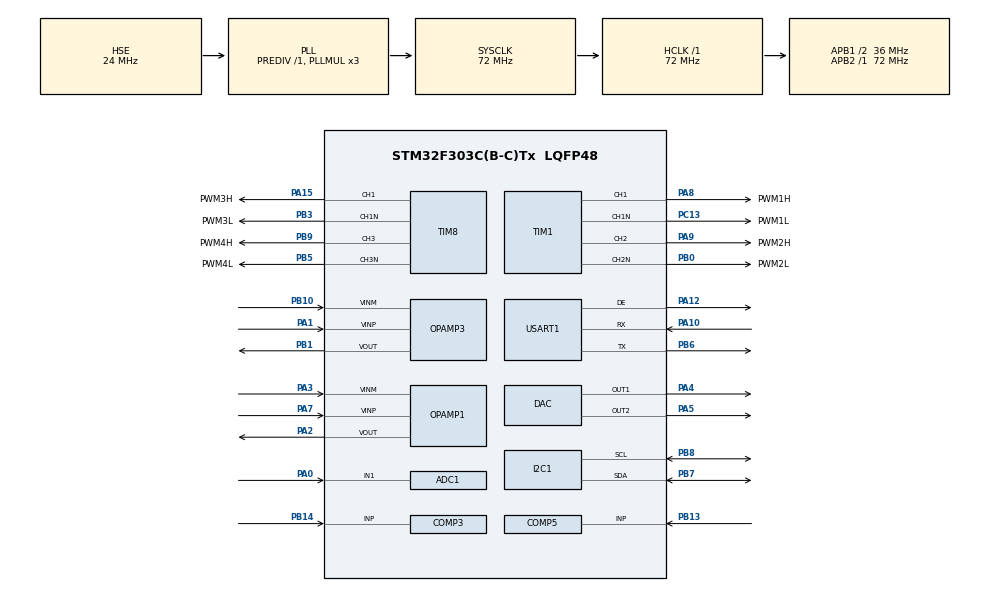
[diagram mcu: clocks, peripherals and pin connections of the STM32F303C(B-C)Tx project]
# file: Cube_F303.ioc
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ADC1.Channel-0\#ChannelRegularConversion=ADC_CHANNEL_VBAT
ADC1.NbrOfConversionFlag=1
ADC1.Offset-0\#ChannelRegularConversion=0
ADC1.OffsetNumber-0\#ChannelRegularConversion=ADC_OFFSET_NONE
ADC1.Rank-0\#ChannelRegularConversion=1
ADC1.SamplingTime-0\#ChannelRegularConversion=ADC_SAMPLETIME_1CYCLE_5
ADC1.master=1
COMP3.InvertingInput=COMP_INVERTINGINPUT_DAC1_CH1
COMP5.InvertingInput=COMP_INVERTINGINPUT_DAC1_CH2
Dma.ADC1.0.Direction=DMA_PERIPH_TO_MEMORY
Dma.ADC1.0.Instance=DMA1_Channel1
Dma.ADC1.0.MemDataAlignment=DMA_MDATAALIGN_HALFWORD
Dma.ADC1.0.MemInc=DMA_MINC_ENABLE
Dma.ADC1.0.Mode=DMA_CIRCULAR
Dma.ADC1.0.PeriphDataAlignment=DMA_PDATAALIGN_HALFWORD
Dma.ADC1.0.PeriphInc=DMA_PINC_DISABLE
Dma.ADC1.0.Priority=DMA_PRIORITY_LOW
Dma.Request0=ADC1
Mcu.Family=STM32F3
Mcu.Name=STM32F303C(B-C)Tx
Mcu.Package=LQFP48
NVIC.DMA1_Channel1_IRQn=true\:0\:0\:false\:false\:true
NVIC.PriorityGroup=NVIC_PRIORITYGROUP_4
NVIC.TIM6_DAC_IRQn=true\:0\:0\:false\:false\:true
PA0.Mode=IN1-Single-Ended
PA0.Signal=ADC1_IN1
PA1.Mode=Standalone
PA1.Signal=OPAMP3_VINP
PA10.Mode=Asynchronous
PA10.Signal=USART1_RX
PA12.Mode=Hardware Flow Control (RS485)
PA12.Signal=USART1_DE
PA13.Mode=Serial_Wire
PA13.Signal=SYS_JTMS-SWDIO
PA14.Mode=Serial_Wire
PA14.Signal=SYS_JTCK-SWCLK
PA15.GPIO_Label=PWM3H
PA15.Signal=S_TIM8_CH1
PA2.Mode=Standalone
PA2.Signal=OPAMP1_VOUT
PA3.Mode=Standalone
PA3.Signal=OPAMP1_VINM
PA4.Signal=COMP_DAC1_group
PA5.Signal=COMP_DAC2_group
PA7.Mode=Standalone
PA7.Signal=OPAMP1_VINP
PA8.GPIO_Label=PWM1H
PA8.Signal=S_TIM1_CH1
PA9.GPIO_Label=PWM2H
PA9.Signal=S_TIM1_CH2
PB0.GPIO_Label=PWM2L
PB0.Mode=Output Compare2 CH2 CH2N
PB0.Signal=TIM1_CH2N
PB1.Mode=Standalone
PB1.Signal=OPAMP3_VOUT
PB10.Mode=Standalone
PB10.Signal=OPAMP3_VINM
PB13.Mode=INP
PB13.Signal=COMP5_INP
PB14.Mode=INP
PB14.Signal=COMP3_INP
PB3.GPIO_Label=PWM3L
PB3.Mode=Output Compare1 CH1 CH1N
PB3.Signal=TIM8_CH1N
PB5.GPIO_Label=PWM4L
PB5.Mode=Output Compare3 CH3 CH3N
PB5.Signal=TIM8_CH3N
PB6.Mode=Asynchronous
PB6.Signal=USART1_TX
PB7.Mode=I2C
PB7.Signal=I2C1_SDA
PB8.Mode=I2C
PB8.Signal=I2C1_SCL
PB9.GPIO_Label=PWM4H
PB9.Signal=S_TIM8_CH3
PC13.GPIO_Label=PWM1L
PC13.Mode=Output Compare1 CH1 CH1N
PC13.Signal=TIM1_CH1N
PF0-OSC_IN.Mode=HSE-External-Oscillator
PF0-OSC_IN.Signal=RCC_OSC_IN
PF1-OSC_OUT.Mode=HSE-External-Oscillator
PF1-OSC_OUT.Signal=RCC_OSC_OUT
ProjectManager.HeapSize=0x200
ProjectManager.StackSize=0x400
ProjectManager.TargetToolchain=Other Toolchains (GPDSC)
RCC.AHBFreq_Value=72000000
RCC.APB1CLKDivider=RCC_HCLK_DIV2
RCC.APB1Freq_Value=36000000
RCC.APB1TimFreq_Value=72000000
RCC.APB2Freq_Value=72000000
RCC.APB2TimFreq_Value=72000000
RCC.CortexFreq_Value=9000000
RCC.Cortex_Div=SYSTICK_CLKSOURCE_HCLK_DIV8
RCC.HCLKFreq_Value=72000000
RCC.HSE_VALUE=24000000
RCC.HSI_VALUE=8000000
RCC.LSE_VALUE=32768
RCC.PLLMUL=RCC_PLL_MUL3
RCC.PLLSourceVirtual=RCC_PLLSOURCE_HSE
RCC.SYSCLKFreq_VALUE=72000000
RCC.TIM1Selection=RCC_TIM1CLK_PLLCLK
RCC.TIM8Selection=RCC_TIM8CLK_PLLCLK
RCC.USBFreq_Value=72000000
RCC.Usart1ClockSelection=RCC_USART1CLKSOURCE_HSI
SH.COMP_DAC1_group.0=DAC_OUT1,DAC_OUT1
SH.COMP_DAC2_group.0=DAC_OUT2,Enable_DAC_OUT2
SH.S_TIM1_CH1.0=TIM1_CH1,Output Compare1 CH1 CH1N
SH.S_TIM1_CH2.0=TIM1_CH2,Output Compare2 CH2 CH2N
SH.S_TIM8_CH1.0=TIM8_CH1,Output Compare1 CH1 CH1N
SH.S_TIM8_CH3.0=TIM8_CH3,Output Compare3 CH3 CH3N
TIM1.Channel-Output\ Compare1\ CH1\ CH1N=TIM_CHANNEL_1
TIM1.Channel-Output\ Compare2\ CH2\ CH2N=TIM_CHANNEL_2
TIM6.Period=1000
TIM8.Channel-Output\ Compare1\ CH1\ CH1N=TIM_CHANNEL_1
TIM8.Channel-Output\ Compare3\ CH3\ CH3N=TIM_CHANNEL_3
USART1.VirtualMode-Asynchronous=VM_ASYNC
USART1.VirtualMode-Hardware\ Flow\ Control\ (RS485)=VM_ASYNC
VP_ADC1_TempSens_Input.Mode=IN-TempSens
VP_ADC1_Vbat_Input.Mode=IN-Vbat
VP_COMP3_VS_DAC1OUT1.Mode=INM_DACOUT1
VP_COMP5_VS_DAC1OUT2.Mode=INM_DACOUT2
VP_CRC_VS_CRC.Mode=CRC_Activate
VP_TIM6_VS_ClockSourceINT.Mode=Enable_Timer
board=Cube_F303

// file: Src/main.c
/**
  ******************************************************************************
  * File Name          : main.c
  * Description        : Main program body
  ******************************************************************************
  ** This notice applies to any and all portions of this file
  * that are not between comment pairs USER CODE BEGIN and
  * USER CODE END. Other portions of this file, whether
  * inserted by the user or by software development tools
  * are owned by their respective copyright owners.
  *
  * COPYRIGHT(c) 2017 STMicroelectronics
  *
  * Redistribution and use in source and binary forms, with or without modification,
  * are permitted provided that the following conditions are met:
  *   1. Redistributions of source code must retain the above copyright notice,
  *      this list of conditions and the following disclaimer.
  *   2. Redistributions in binary form must reproduce the above copyright notice,
  *      this list of conditions and the following disclaimer in the documentation
  *      and/or other materials provided with the distribution.
  *   3. Neither the name of STMicroelectronics nor the names of its contributors
  *      may be used to endorse or promote products derived from this software
  *      without specific prior written permission.
  *
  * THIS SOFTWARE IS PROVIDED BY THE COPYRIGHT HOLDERS AND CONTRIBUTORS "AS IS"
  * AND ANY EXPRESS OR IMPLIED WARRANTIES, INCLUDING, BUT NOT LIMITED TO, THE
  * IMPLIED WARRANTIES OF MERCHANTABILITY AND FITNESS FOR A PARTICULAR PURPOSE ARE
  * DISCLAIMED. IN NO EVENT SHALL THE COPYRIGHT HOLDER OR CONTRIBUTORS BE LIABLE
  * FOR ANY DIRECT, INDIRECT, INCIDENTAL, SPECIAL, EXEMPLARY, OR CONSEQUENTIAL
  * DAMAGES (INCLUDING, BUT NOT LIMITED TO, PROCUREMENT OF SUBSTITUTE GOODS OR
  * SERVICES; LOSS OF USE, DATA, OR PROFITS; OR BUSINESS INTERRUPTION) HOWEVER
  * CAUSED AND ON ANY THEORY OF LIABILITY, WHETHER IN CONTRACT, STRICT LIABILITY,
  * OR TORT (INCLUDING NEGLIGENCE OR OTHERWISE) ARISING IN ANY WAY OUT OF THE USE
  * OF THIS SOFTWARE, EVEN IF ADVISED OF THE POSSIBILITY OF SUCH DAMAGE.
  *
  ******************************************************************************
  */
#include "main.h"
#include "stm32f3xx_hal.h"

/* USER CODE BEGIN Includes */
#include "irq.h"
/* USER CODE END Includes */

ADC_HandleTypeDef hadc1;
DMA_HandleTypeDef hdma_adc1;

COMP_HandleTypeDef hcomp3;
COMP_HandleTypeDef hcomp5;

CRC_HandleTypeDef hcrc;

DAC_HandleTypeDef hdac;

I2C_HandleTypeDef hi2c1;

OPAMP_HandleTypeDef hopamp1;
OPAMP_HandleTypeDef hopamp3;

TIM_HandleTypeDef htim1;
TIM_HandleTypeDef htim6;
TIM_HandleTypeDef htim8;

UART_HandleTypeDef huart1;

/* USER CODE BEGIN PV */

/**
Timer TIM6 delay formavimas

*/

/* Private variables ---------------------------------------------------------*/

/* USER CODE END PV */

void SystemClock_Config(void);
static void MX_GPIO_Init(void);
static void MX_DMA_Init(void);
static void MX_DAC_Init(void);
static void MX_I2C1_Init(void);
static void MX_USART1_UART_Init(void);
static void MX_TIM1_Init(void);
static void MX_TIM8_Init(void);
static void MX_OPAMP1_Init(void);
static void MX_OPAMP3_Init(void);
static void MX_COMP3_Init(void);
static void MX_COMP5_Init(void);
static void MX_ADC1_Init(void);
static void MX_TIM6_Init(void);
static void MX_CRC_Init(void);

void HAL_TIM_MspPostInit(TIM_HandleTypeDef *htim);

/* USER CODE BEGIN PFP */
/* Private function prototypes -----------------------------------------------*/

/* USER CODE END PFP */

int main(void)
{

  /* USER CODE BEGIN 1 */
    disable_interrupts();
  /* USER CODE END 1 */

  /* MCU Configuration----------------------------------------------------------*/

  /* Reset of all peripherals, Initializes the Flash interface and the Systick. */
  HAL_Init();

  /* Configure the system clock */
  SystemClock_Config();

  /* Initialize all configured peripherals */
  MX_GPIO_Init();
  MX_DMA_Init();
  MX_DAC_Init();
  MX_I2C1_Init();
  MX_USART1_UART_Init();
  MX_TIM1_Init();
  MX_TIM8_Init();
  MX_OPAMP1_Init();
  MX_OPAMP3_Init();
  MX_COMP3_Init();
  MX_COMP5_Init();
  MX_ADC1_Init();
  MX_TIM6_Init();
  MX_CRC_Init();

  /* Infinite loop */
  while (1)
  {

  }

}

/** System Clock Configuration
*/
void SystemClock_Config(void)
{

  RCC_OscInitTypeDef RCC_OscInitStruct;
  RCC_ClkInitTypeDef RCC_ClkInitStruct;
  RCC_PeriphCLKInitTypeDef PeriphClkInit;

    /**Initializes the CPU, AHB and APB busses clocks
    */
  RCC_OscInitStruct.OscillatorType = RCC_OSCILLATORTYPE_HSI|RCC_OSCILLATORTYPE_HSE;
  RCC_OscInitStruct.HSEState = RCC_HSE_ON;
  RCC_OscInitStruct.HSEPredivValue = RCC_HSE_PREDIV_DIV1;
  RCC_OscInitStruct.HSIState = RCC_HSI_ON;
  RCC_OscInitStruct.HSICalibrationValue = 16;
  RCC_OscInitStruct.PLL.PLLState = RCC_PLL_ON;
  RCC_OscInitStruct.PLL.PLLSource = RCC_PLLSOURCE_HSE;
  RCC_OscInitStruct.PLL.PLLMUL = RCC_PLL_MUL3;
  if (HAL_RCC_OscConfig(&RCC_OscInitStruct) != HAL_OK)
  {
    _Error_Handler(__FILE__, __LINE__);
  }

    /**Initializes the CPU, AHB and APB busses clocks
    */
  RCC_ClkInitStruct.ClockType = RCC_CLOCKTYPE_HCLK|RCC_CLOCKTYPE_SYSCLK
                              |RCC_CLOCKTYPE_PCLK1|RCC_CLOCKTYPE_PCLK2;
  RCC_ClkInitStruct.SYSCLKSource = RCC_SYSCLKSOURCE_PLLCLK;
  RCC_ClkInitStruct.AHBCLKDivider = RCC_SYSCLK_DIV1;
  RCC_ClkInitStruct.APB1CLKDivider = RCC_HCLK_DIV2;
  RCC_ClkInitStruct.APB2CLKDivider = RCC_HCLK_DIV1;

  if (HAL_RCC_ClockConfig(&RCC_ClkInitStruct, FLASH_LATENCY_2) != HAL_OK)
  {
    _Error_Handler(__FILE__, __LINE__);
  }

  PeriphClkInit.PeriphClockSelection = RCC_PERIPHCLK_USART1|RCC_PERIPHCLK_I2C1
                              |RCC_PERIPHCLK_TIM1|RCC_PERIPHCLK_TIM8
                              |RCC_PERIPHCLK_ADC12;
  PeriphClkInit.Usart1ClockSelection = RCC_USART1CLKSOURCE_HSI;
  PeriphClkInit.Adc12ClockSelection = RCC_ADC12PLLCLK_DIV1;
  PeriphClkInit.I2c1ClockSelection = RCC_I2C1CLKSOURCE_HSI;
  PeriphClkInit.Tim1ClockSelection = RCC_TIM1CLK_PLLCLK;
  PeriphClkInit.Tim8ClockSelection = RCC_TIM8CLK_PLLCLK;
  if (HAL_RCCEx_PeriphCLKConfig(&PeriphClkInit) != HAL_OK)
  {
    _Error_Handler(__FILE__, __LINE__);
  }

    /**Configure the Systick interrupt time
    */
  HAL_SYSTICK_Config(HAL_RCC_GetHCLKFreq()/8000);

    /**Configure the Systick
    */
  HAL_SYSTICK_CLKSourceConfig(SYSTICK_CLKSOURCE_HCLK_DIV8);

  /* SysTick_IRQn interrupt configuration */
  HAL_NVIC_SetPriority(SysTick_IRQn, 0, 0);
}

/* ADC1 init function */
static void MX_ADC1_Init(void)
{

  ADC_MultiModeTypeDef multimode;
  ADC_ChannelConfTypeDef sConfig;

    /**Common config
    */
  hadc1.Instance = ADC1;
  hadc1.Init.ClockPrescaler = ADC_CLOCK_ASYNC_DIV1;
  hadc1.Init.Resolution = ADC_RESOLUTION_12B;
  hadc1.Init.ScanConvMode = ADC_SCAN_DISABLE;
  hadc1.Init.ContinuousConvMode = DISABLE;
  hadc1.Init.DiscontinuousConvMode = DISABLE;
  hadc1.Init.ExternalTrigConvEdge = ADC_EXTERNALTRIGCONVEDGE_NONE;
  hadc1.Init.ExternalTrigConv = ADC_SOFTWARE_START;
  hadc1.Init.DataAlign = ADC_DATAALIGN_RIGHT;
  hadc1.Init.NbrOfConversion = 1;
  hadc1.Init.DMAContinuousRequests = DISABLE;
  hadc1.Init.EOCSelection = ADC_EOC_SINGLE_CONV;
  hadc1.Init.LowPowerAutoWait = DISABLE;
  hadc1.Init.Overrun = ADC_OVR_DATA_OVERWRITTEN;
  if (HAL_ADC_Init(&hadc1) != HAL_OK)
  {
    _Error_Handler(__FILE__, __LINE__);
  }

    /**Configure the ADC multi-mode
    */
  multimode.Mode = ADC_MODE_INDEPENDENT;
  if (HAL_ADCEx_MultiModeConfigChannel(&hadc1, &multimode) != HAL_OK)
  {
    _Error_Handler(__FILE__, __LINE__);
  }

    /**Configure Regular Channel
    */
  sConfig.Channel = ADC_CHANNEL_VBAT;
  sConfig.Rank = 1;
  sConfig.SingleDiff = ADC_SINGLE_ENDED;
  sConfig.SamplingTime = ADC_SAMPLETIME_1CYCLE_5;
  sConfig.OffsetNumber = ADC_OFFSET_NONE;
  sConfig.Offset = 0;
  if (HAL_ADC_ConfigChannel(&hadc1, &sConfig) != HAL_OK)
  {
    _Error_Handler(__FILE__, __LINE__);
  }

}

/* COMP3 init function */
static void MX_COMP3_Init(void)
{

  hcomp3.Instance = COMP3;
  hcomp3.Init.InvertingInput = COMP_INVERTINGINPUT_DAC1_CH1;
  hcomp3.Init.NonInvertingInput = COMP_NONINVERTINGINPUT_IO1;
  hcomp3.Init.Output = COMP_OUTPUT_NONE;
  hcomp3.Init.OutputPol = COMP_OUTPUTPOL_NONINVERTED;
  hcomp3.Init.Hysteresis = COMP_HYSTERESIS_NONE;
  hcomp3.Init.BlankingSrce = COMP_BLANKINGSRCE_NONE;
  hcomp3.Init.Mode = COMP_MODE_HIGHSPEED;
  hcomp3.Init.WindowMode = COMP_WINDOWMODE_DISABLE;
  hcomp3.Init.TriggerMode = COMP_TRIGGERMODE_NONE;
  if (HAL_COMP_Init(&hcomp3) != HAL_OK)
  {
    _Error_Handler(__FILE__, __LINE__);
  }

}

/* COMP5 init function */
static void MX_COMP5_Init(void)
{

  hcomp5.Instance = COMP5;
  hcomp5.Init.InvertingInput = COMP_INVERTINGINPUT_DAC1_CH2;
  hcomp5.Init.NonInvertingInput = COMP_NONINVERTINGINPUT_IO2;
  hcomp5.Init.Output = COMP_OUTPUT_NONE;
  hcomp5.Init.OutputPol = COMP_OUTPUTPOL_NONINVERTED;
  hcomp5.Init.Hysteresis = COMP_HYSTERESIS_NONE;
  hcomp5.Init.BlankingSrce = COMP_BLANKINGSRCE_NONE;
  hcomp5.Init.Mode = COMP_MODE_HIGHSPEED;
  hcomp5.Init.WindowMode = COMP_WINDOWMODE_DISABLE;
  hcomp5.Init.TriggerMode = COMP_TRIGGERMODE_NONE;
  if (HAL_COMP_Init(&hcomp5) != HAL_OK)
  {
    _Error_Handler(__FILE__, __LINE__);
  }

}

/* CRC init function */
static void MX_CRC_Init(void)
{

  hcrc.Instance = CRC;
  hcrc.Init.DefaultPolynomialUse = DEFAULT_POLYNOMIAL_ENABLE;
  hcrc.Init.DefaultInitValueUse = DEFAULT_INIT_VALUE_ENABLE;
  hcrc.Init.InputDataInversionMode = CRC_INPUTDATA_INVERSION_NONE;
  hcrc.Init.OutputDataInversionMode = CRC_OUTPUTDATA_INVERSION_DISABLE;
  hcrc.InputDataFormat = CRC_INPUTDATA_FORMAT_BYTES;
  if (HAL_CRC_Init(&hcrc) != HAL_OK)
  {
    _Error_Handler(__FILE__, __LINE__);
  }

}

/* DAC init function */
static void MX_DAC_Init(void)
{

  DAC_ChannelConfTypeDef sConfig;

    /**DAC Initialization
    */
  hdac.Instance = DAC;
  if (HAL_DAC_Init(&hdac) != HAL_OK)
  {
    _Error_Handler(__FILE__, __LINE__);
  }

    /**DAC channel OUT1 config
    */
  sConfig.DAC_Trigger = DAC_TRIGGER_NONE;
  sConfig.DAC_OutputBuffer = DAC_OUTPUTBUFFER_ENABLE;
  if (HAL_DAC_ConfigChannel(&hdac, &sConfig, DAC_CHANNEL_1) != HAL_OK)
  {
    _Error_Handler(__FILE__, __LINE__);
  }

    /**DAC channel OUT2 config
    */
  if (HAL_DAC_ConfigChannel(&hdac, &sConfig, DAC_CHANNEL_2) != HAL_OK)
  {
    _Error_Handler(__FILE__, __LINE__);
  }

}

/* I2C1 init function */
static void MX_I2C1_Init(void)
{

  hi2c1.Instance = I2C1;
  hi2c1.Init.Timing = 0x2000090E;
  hi2c1.Init.OwnAddress1 = 0;
  hi2c1.Init.AddressingMode = I2C_ADDRESSINGMODE_7BIT;
  hi2c1.Init.DualAddressMode = I2C_DUALADDRESS_DISABLE;
  hi2c1.Init.OwnAddress2 = 0;
  hi2c1.Init.OwnAddress2Masks = I2C_OA2_NOMASK;
  hi2c1.Init.GeneralCallMode = I2C_GENERALCALL_DISABLE;
  hi2c1.Init.NoStretchMode = I2C_NOSTRETCH_DISABLE;
  if (HAL_I2C_Init(&hi2c1) != HAL_OK)
  {
    _Error_Handler(__FILE__, __LINE__);
  }

    /**Configure Analogue filter
    */
  if (HAL_I2CEx_ConfigAnalogFilter(&hi2c1, I2C_ANALOGFILTER_ENABLE) != HAL_OK)
  {
    _Error_Handler(__FILE__, __LINE__);
  }

    /**Configure Digital filter
    */
  if (HAL_I2CEx_ConfigDigitalFilter(&hi2c1, 0) != HAL_OK)
  {
    _Error_Handler(__FILE__, __LINE__);
  }

}

/* OPAMP1 init function */
static void MX_OPAMP1_Init(void)
{

  hopamp1.Instance = OPAMP1;
  hopamp1.Init.Mode = OPAMP_STANDALONE_MODE;
  hopamp1.Init.NonInvertingInput = OPAMP_NONINVERTINGINPUT_IO1;
  hopamp1.Init.InvertingInput = OPAMP_INVERTINGINPUT_IO1;
  hopamp1.Init.TimerControlledMuxmode = OPAMP_TIMERCONTROLLEDMUXMODE_DISABLE;
  hopamp1.Init.UserTrimming = OPAMP_TRIMMING_FACTORY;
  if (HAL_OPAMP_Init(&hopamp1) != HAL_OK)
  {
    _Error_Handler(__FILE__, __LINE__);
  }

}

/* OPAMP3 init function */
static void MX_OPAMP3_Init(void)
{

  hopamp3.Instance = OPAMP3;
  hopamp3.Init.Mode = OPAMP_STANDALONE_MODE;
  hopamp3.Init.NonInvertingInput = OPAMP_NONINVERTINGINPUT_IO2;
  hopamp3.Init.InvertingInput = OPAMP_INVERTINGINPUT_IO0;
  hopamp3.Init.TimerControlledMuxmode = OPAMP_TIMERCONTROLLEDMUXMODE_DISABLE;
  hopamp3.Init.UserTrimming = OPAMP_TRIMMING_FACTORY;
  if (HAL_OPAMP_Init(&hopamp3) != HAL_OK)
  {
    _Error_Handler(__FILE__, __LINE__);
  }

}

/* TIM1 init function */
static void MX_TIM1_Init(void)
{

  TIM_MasterConfigTypeDef sMasterConfig;
  TIM_OC_InitTypeDef sConfigOC;
  TIM_BreakDeadTimeConfigTypeDef sBreakDeadTimeConfig;

  htim1.Instance = TIM1;
  htim1.Init.Prescaler = 0;
  htim1.Init.CounterMode = TIM_COUNTERMODE_UP;
  htim1.Init.Period = 0;
  htim1.Init.ClockDivision = TIM_CLOCKDIVISION_DIV1;
  htim1.Init.RepetitionCounter = 0;
  htim1.Init.AutoReloadPreload = TIM_AUTORELOAD_PRELOAD_DISABLE;
  if (HAL_TIM_OC_Init(&htim1) != HAL_OK)
  {
    _Error_Handler(__FILE__, __LINE__);
  }

  sMasterConfig.MasterOutputTrigger = TIM_TRGO_RESET;
  sMasterConfig.MasterOutputTrigger2 = TIM_TRGO2_RESET;
  sMasterConfig.MasterSlaveMode = TIM_MASTERSLAVEMODE_DISABLE;
  if (HAL_TIMEx_MasterConfigSynchronization(&htim1, &sMasterConfig) != HAL_OK)
  {
    _Error_Handler(__FILE__, __LINE__);
  }

  sConfigOC.OCMode = TIM_OCMODE_TIMING;
  sConfigOC.Pulse = 0;
  sConfigOC.OCPolarity = TIM_OCPOLARITY_HIGH;
  sConfigOC.OCNPolarity = TIM_OCNPOLARITY_HIGH;
  sConfigOC.OCFastMode = TIM_OCFAST_DISABLE;
  sConfigOC.OCIdleState = TIM_OCIDLESTATE_RESET;
  sConfigOC.OCNIdleState = TIM_OCNIDLESTATE_RESET;
  if (HAL_TIM_OC_ConfigChannel(&htim1, &sConfigOC, TIM_CHANNEL_1) != HAL_OK)
  {
    _Error_Handler(__FILE__, __LINE__);
  }

  if (HAL_TIM_OC_ConfigChannel(&htim1, &sConfigOC, TIM_CHANNEL_2) != HAL_OK)
  {
    _Error_Handler(__FILE__, __LINE__);
  }

  sBreakDeadTimeConfig.OffStateRunMode = TIM_OSSR_DISABLE;
  sBreakDeadTimeConfig.OffStateIDLEMode = TIM_OSSI_DISABLE;
  sBreakDeadTimeConfig.LockLevel = TIM_LOCKLEVEL_OFF;
  sBreakDeadTimeConfig.DeadTime = 0;
  sBreakDeadTimeConfig.BreakState = TIM_BREAK_DISABLE;
  sBreakDeadTimeConfig.BreakPolarity = TIM_BREAKPOLARITY_HIGH;
  sBreakDeadTimeConfig.BreakFilter = 0;
  sBreakDeadTimeConfig.Break2State = TIM_BREAK2_DISABLE;
  sBreakDeadTimeConfig.Break2Polarity = TIM_BREAK2POLARITY_HIGH;
  sBreakDeadTimeConfig.Break2Filter = 0;
  sBreakDeadTimeConfig.AutomaticOutput = TIM_AUTOMATICOUTPUT_DISABLE;
  if (HAL_TIMEx_ConfigBreakDeadTime(&htim1, &sBreakDeadTimeConfig) != HAL_OK)
  {
    _Error_Handler(__FILE__, __LINE__);
  }

  HAL_TIM_MspPostInit(&htim1);

}

/* TIM6 init function */
static void MX_TIM6_Init(void)
{

  TIM_MasterConfigTypeDef sMasterConfig;

  htim6.Instance = TIM6;
  htim6.Init.Prescaler = 0;
  htim6.Init.CounterMode = TIM_COUNTERMODE_UP;
  htim6.Init.Period = 1000;
  htim6.Init.AutoReloadPreload = TIM_AUTORELOAD_PRELOAD_DISABLE;
  if (HAL_TIM_Base_Init(&htim6) != HAL_OK)
  {
    _Error_Handler(__FILE__, __LINE__);
  }

  sMasterConfig.MasterOutputTrigger = TIM_TRGO_RESET;
  sMasterConfig.MasterSlaveMode = TIM_MASTERSLAVEMODE_DISABLE;
  if (HAL_TIMEx_MasterConfigSynchronization(&htim6, &sMasterConfig) != HAL_OK)
  {
    _Error_Handler(__FILE__, __LINE__);
  }

}

/* TIM8 init function */
static void MX_TIM8_Init(void)
{

  TIM_MasterConfigTypeDef sMasterConfig;
  TIM_OC_InitTypeDef sConfigOC;
  TIM_BreakDeadTimeConfigTypeDef sBreakDeadTimeConfig;

  htim8.Instance = TIM8;
  htim8.Init.Prescaler = 0;
  htim8.Init.CounterMode = TIM_COUNTERMODE_UP;
  htim8.Init.Period = 0;
  htim8.Init.ClockDivision = TIM_CLOCKDIVISION_DIV1;
  htim8.Init.RepetitionCounter = 0;
  htim8.Init.AutoReloadPreload = TIM_AUTORELOAD_PRELOAD_DISABLE;
  if (HAL_TIM_OC_Init(&htim8) != HAL_OK)
  {
    _Error_Handler(__FILE__, __LINE__);
  }

  sMasterConfig.MasterOutputTrigger = TIM_TRGO_RESET;
  sMasterConfig.MasterOutputTrigger2 = TIM_TRGO2_RESET;
  sMasterConfig.MasterSlaveMode = TIM_MASTERSLAVEMODE_DISABLE;
  if (HAL_TIMEx_MasterConfigSynchronization(&htim8, &sMasterConfig) != HAL_OK)
  {
    _Error_Handler(__FILE__, __LINE__);
  }

  sConfigOC.OCMode = TIM_OCMODE_TIMING;
  sConfigOC.Pulse = 0;
  sConfigOC.OCPolarity = TIM_OCPOLARITY_HIGH;
  sConfigOC.OCNPolarity = TIM_OCNPOLARITY_HIGH;
  sConfigOC.OCFastMode = TIM_OCFAST_DISABLE;
  sConfigOC.OCIdleState = TIM_OCIDLESTATE_RESET;
  sConfigOC.OCNIdleState = TIM_OCNIDLESTATE_RESET;
  if (HAL_TIM_OC_ConfigChannel(&htim8, &sConfigOC, TIM_CHANNEL_1) != HAL_OK)
  {
    _Error_Handler(__FILE__, __LINE__);
  }

  if (HAL_TIM_OC_ConfigChannel(&htim8, &sConfigOC, TIM_CHANNEL_3) != HAL_OK)
  {
    _Error_Handler(__FILE__, __LINE__);
  }

  sBreakDeadTimeConfig.OffStateRunMode = TIM_OSSR_DISABLE;
  sBreakDeadTimeConfig.OffStateIDLEMode = TIM_OSSI_DISABLE;
  sBreakDeadTimeConfig.LockLevel = TIM_LOCKLEVEL_OFF;
  sBreakDeadTimeConfig.DeadTime = 0;
  sBreakDeadTimeConfig.BreakState = TIM_BREAK_DISABLE;
  sBreakDeadTimeConfig.BreakPolarity = TIM_BREAKPOLARITY_HIGH;
  sBreakDeadTimeConfig.BreakFilter = 0;
  sBreakDeadTimeConfig.Break2State = TIM_BREAK2_DISABLE;
  sBreakDeadTimeConfig.Break2Polarity = TIM_BREAK2POLARITY_HIGH;
  sBreakDeadTimeConfig.Break2Filter = 0;
  sBreakDeadTimeConfig.AutomaticOutput = TIM_AUTOMATICOUTPUT_DISABLE;
  if (HAL_TIMEx_ConfigBreakDeadTime(&htim8, &sBreakDeadTimeConfig) != HAL_OK)
  {
    _Error_Handler(__FILE__, __LINE__);
  }

  HAL_TIM_MspPostInit(&htim8);

}

/* USART1 init function */
static void MX_USART1_UART_Init(void)
{

  huart1.Instance = USART1;
  huart1.Init.BaudRate = 38400;
  huart1.Init.WordLength = UART_WORDLENGTH_8B;
  huart1.Init.StopBits = UART_STOPBITS_1;
  huart1.Init.Parity = UART_PARITY_NONE;
  huart1.Init.Mode = UART_MODE_TX_RX;
  huart1.Init.HwFlowCtl = UART_HWCONTROL_NONE;
  huart1.Init.OverSampling = UART_OVERSAMPLING_16;
  huart1.Init.OneBitSampling = UART_ONE_BIT_SAMPLE_DISABLE;
  huart1.AdvancedInit.AdvFeatureInit = UART_ADVFEATURE_NO_INIT;
  if (HAL_RS485Ex_Init(&huart1, UART_DE_POLARITY_HIGH, 0, 0) != HAL_OK)
  {
    _Error_Handler(__FILE__, __LINE__);
  }

}

static void MX_DMA_Init(void)
{
  /* DMA controller clock enable */
  __HAL_RCC_DMA1_CLK_ENABLE();

  /* DMA interrupt init */
  /* DMA1_Channel1_IRQn interrupt configuration */
  HAL_NVIC_SetPriority(DMA1_Channel1_IRQn, 0, 0);
  HAL_NVIC_EnableIRQ(DMA1_Channel1_IRQn);

}

/** Configure pins as
        * Analog
        * Input
        * Output
        * EVENT_OUT
        * EXTI
*/
static void MX_GPIO_Init(void)
{

  /* GPIO Ports Clock Enable */
  __HAL_RCC_GPIOC_CLK_ENABLE();
  __HAL_RCC_GPIOF_CLK_ENABLE();
  __HAL_RCC_GPIOA_CLK_ENABLE();
  __HAL_RCC_GPIOB_CLK_ENABLE();

}

/* USER CODE BEGIN 4 */

void HAL_SYSTICK_Callback(void){

}

/* USER CODE END 4 */

void _Error_Handler(char * file, int line)
{
  while(1)
  {
  }
}

/************************ (C) COPYRIGHT STMicroelectronics *****END OF FILE****/
